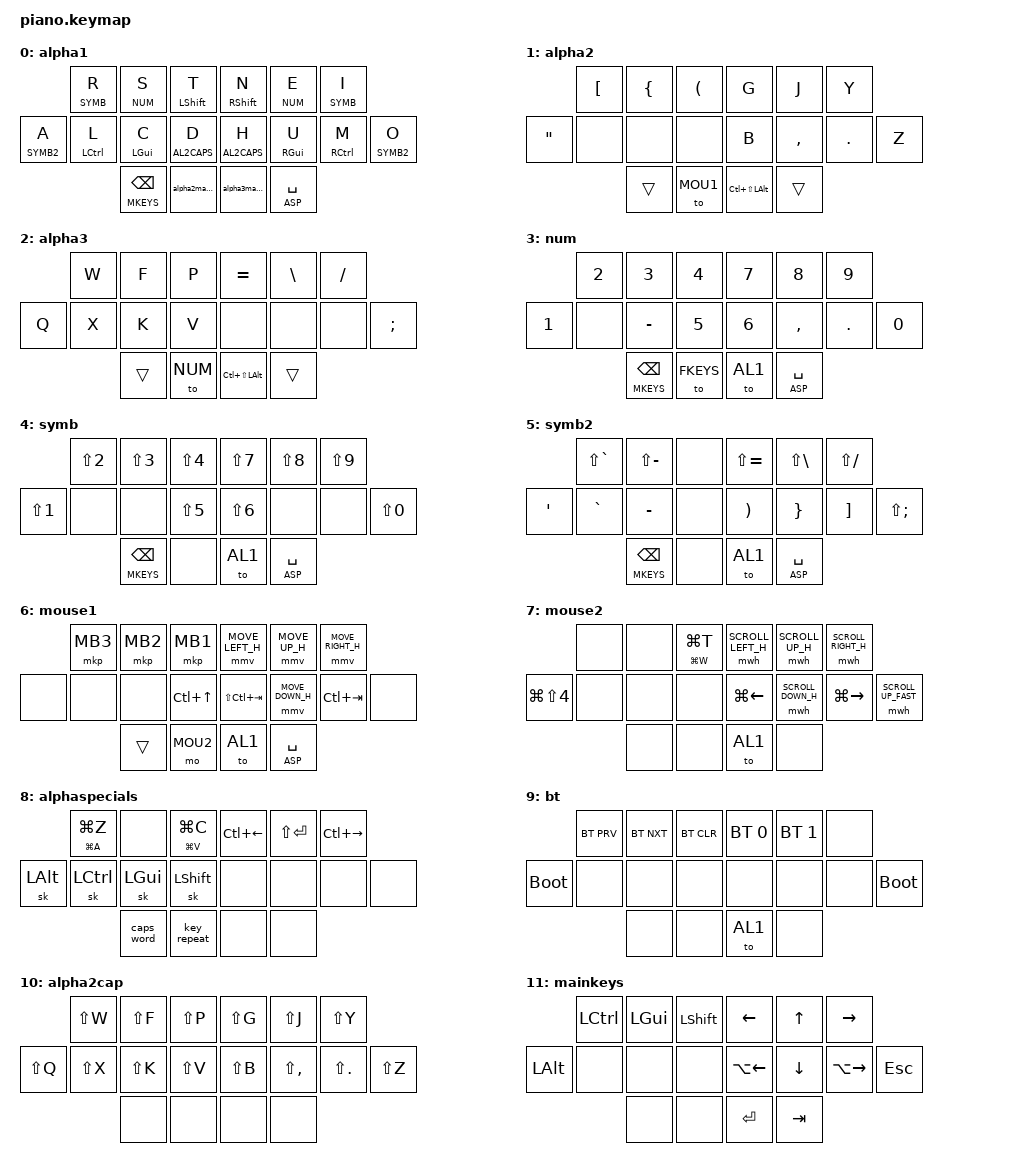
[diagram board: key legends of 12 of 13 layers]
/*
 * Copyright (c) 2020 The ZMK Contributors
 *
 * SPDX-License-Identifier: MIT
 */

#include <behaviors.dtsi>
#include <dt-bindings/zmk/keys.h>
#include <dt-bindings/zmk/bt.h>
#include <dt-bindings/zmk/mouse.h>

/* #define BL_ON_CMD 0 */
/* #define BL_OFF_CMD 1 */
/* #define BL_ON BL_ON_CMD 0 */
/* #define BL_OFF BL_OFF_CMD 0 */

#define M_MOVE_SPEED 1600
#define MOVE_UP_H MOVE_VERT(-M_MOVE_SPEED)
#define MOVE_DOWN_H MOVE_VERT(M_MOVE_SPEED)
#define MOVE_LEFT_H MOVE_HOR(-M_MOVE_SPEED)
#define MOVE_RIGHT_H MOVE_HOR(M_MOVE_SPEED)

#define M_SCROLL_SPEED 11
#define SCROLL_UP_H SCROLL_VERT(-M_SCROLL_SPEED)
#define SCROLL_DOWN_H SCROLL_VERT(M_SCROLL_SPEED)
#define SCROLL_LEFT_H SCROLL_HOR(-M_SCROLL_SPEED)
#define SCROLL_RIGHT_H SCROLL_HOR(M_SCROLL_SPEED)

#define SCROLL_UP_FAST SCROLL_VERT(-40)


&mt {
    tapping-term-ms = <201>;
    flavor = "tap-preferred";
 };
&sk {
     release-after-ms = <2000>;
     quick-release;
 };

&mmv {
  delay-ms = <0>;
  time-to-max-speed-ms = <500>;
  acceleration-exponent = <1>;
};

&mwh {
  delay-ms = <0>;
  time-to-max-speed-ms = <250>;
  acceleration-exponent = <0>;
};

/* Layers */
#define AL1       0
#define AL2       1
#define AL3       2
#define NUM       3
#define SYMB      4
#define SYMB2     5
#define MOU1      6
#define MOU2      7
#define ASP       8
#define BT        9
#define AL2CAPS   10
#define MKEYS     11
#define FKEYS     12

/ { 

    behaviors {
        thu_l: homerow_layers_left {
            compatible = "zmk,behavior-hold-tap";
            label = "THUMB_MODS_L";
            #binding-cells = <2>;
            tapping-term-ms = <120>;
            quick-tap-ms = <250>;
            flavor = "tap-preferred";
            bindings = <&mo>, <&kp>;
        };
        thu_r: homerow_layers_right {
            compatible = "zmk,behavior-hold-tap";
            label = "THUMB_MODS_R";
            #binding-cells = <2>;
            tapping-term-ms = <120>;
            quick-tap-ms = <250>;
            flavor = "tap-preferred";
            bindings = <&mo>, <&kp>;
        };
        hm_l: homerow_mods_left {
            compatible = "zmk,behavior-hold-tap";
            label = "HOMEROW_MODS_L";
            #binding-cells = <2>;
            tapping-term-ms = <250>;
            quick-tap-ms = <250>;
            flavor = "tap-preferred";
            bindings = <&kp>, <&kp>;
        };
        hm_r: homerow_mods_right {
            compatible = "zmk,behavior-hold-tap";
            label = "HOMEROW_MODS_R";
            #binding-cells = <2>;
            tapping-term-ms = <250>;
            quick-tap-ms = <250>;
            flavor = "tap-preferred";
            bindings = <&kp>, <&kp>;
        };
        hl_l: homerow_layers_left {
            compatible = "zmk,behavior-hold-tap";
            label = "HOMEROW_LAYERS_L";
            #binding-cells = <2>;
            tapping-term-ms = <250>;
            quick-tap-ms = <250>;
            flavor = "tap-preferred";
            bindings = <&mo>, <&kp>;
        };
        hl_r: homerow_layers_right {
            compatible = "zmk,behavior-hold-tap";
            label = "HOMEROW_LAYERS_R";
            #binding-cells = <2>;
            tapping-term-ms = <250>;
            quick-tap-ms = <250>;
            flavor = "tap-preferred";
            bindings = <&mo>, <&kp>;
        };
        td: tapdance {
            compatible = "zmk,behavior-hold-tap";
            label = "TAPDANCE";
            #binding-cells = <2>;
            tapping-term-ms = <190>;
            quick-tap-ms = <250>;
            flavor = "tap-preferred";
            bindings = <&kp>, <&kp>;
        };
	alpha2macro: behavior_macro_1 {
		compatible = "zmk,behavior-macro";
		label = "MACRO1";
		#binding-cells = <0>;
		bindings = < &sl AL2 >;
	};
	alpha3macro: behavior_macro_2 {
		compatible = "zmk,behavior-macro";
		label = "MACRO2";
		#binding-cells = <0>;
		bindings = < &sl AL3 >;
	};
	/* enter_bt_lay: behavior_macro_3 { */
	/* 	compatible = "zmk,behavior-macro"; */
	/* 	label = "BT backlight ON"; */
	/* 	#binding-cells = <0>; */
	/* 	bindings =    < &to BT > */
 /*                , < &bl BL_ON > */
 /*                ; */
	/* }; */
	/* leave_bt_lay: behavior_macro_4 { */
	/* 	compatible = "zmk,behavior-macro"; */
	/* 	label = "BT backlight OFF"; */
	/* 	#binding-cells = <0>; */
	/* 	bindings =    < &to AL1 > */
 /*                , < &bl BL_OFF > */
 /*                ; */
	/* }; */

    };
// 				0		1		2					3		  4			5
// 		6		7		8		9 				10		11		12 		13
//						14	15 	      16 	  17		
       keymap {
                compatible = "zmk,keymap";
                
    alpha1 {
		bindings = <
		 		            &hl_l SYMB R 	  &hl_l NUM S 	      &hm_l LSHIFT T		  &hm_r RSHIFT N 	  &hl_r NUM E     &hl_r SYMB I	  
		&hl_l SYMB2 A	  &hm_l LCTRL L	  &hm_l LGUI C	      &hl_l AL2CAPS D 	 	&hl_r AL2CAPS H   &hm_r RGUI U    &hm_r RCTRL M  &hl_r SYMB2 O
			 	 		 		                    &thu_l MKEYS BKSP   &alpha2macro        &alpha3macro	    &thu_r ASP SPC	 	
		>;
		};

    alpha2 {
		bindings = <
		 	 	                &kp LEFT_BRACKET 	&kp LEFT_BRACE	  &kp LEFT_PARENTHESIS	  &kp G    	        &kp J			    &kp Y 		
		&kp DOUBLE_QUOTES	 	&none		          &none		          &none                   &kp B 		        &kp COMMA			&kp DOT		&kp Z 
			 	 		 		                          &trans	          &to MOU1                &kp LC(LS(LALT))  &trans
		>;
		};

    alpha3 {
		bindings = <
		 	 	    &kp W 		&kp F		&kp P	 	 	&kp EQUAL    	      &kp BACKSLASH		&kp SLASH 		
		&kp Q	 	&kp X 		&kp K		&kp V 		&none 	            &none			      &none		&kp SEMICOLON 
			 	 		 		      &trans	&to NUM   &kp LC(LS(LALT))    &trans
		>;
		};
		
		num {
		bindings = <
		        &kp N2 	    &kp N3	            &kp N4 		  &kp N7 	  &kp N8		      &kp N9
		&kp N1	&none 	    &kp MINUS		        &kp N5		  &kp N6	  &kp COMMA	      &kp DOT   	&kp N0
		                    &hl_l MKEYS BKSP 		&to FKEYS   &to AL1 	&hl_r ASP SPC  	 
		>;
		};

		symb {
		bindings = <
		            &kp LS(N2) 	&kp LS(N3)	        &kp LS(N4) 		&kp LS(N7) 	  &kp LS(N8)		  &kp LS(N9)
		&kp LS(N1)	&none 	    &none		            &kp LS(N5)		&kp LS(N6)	  &none	          &none   	  &kp LS(N0)
		                        &hl_l MKEYS BKSP 		&none         &to AL1 	    &hl_r ASP SPC  	 
		>;
		};

		symb2 {
		bindings = <
		                    &kp LS(GRAVE) 	&kp LS(MINUS)	    &none 	&kp LS(EQUAL) 	        &kp LS(BACKSLASH)		&kp LS(SLASH)
		&kp SINGLE_QUOTE	  &kp GRAVE 	    &kp MINUS		      &none		&kp RIGHT_PARENTHESIS	  &kp RIGHT_BRACE	    &kp RIGHT_BRACKET   &kp LS(SEMICOLON)
		                                    &hl_l MKEYS BKSP  &none   &to AL1 	              &hl_r ASP SPC  	 
		>;
		};

		mouse1 {
		bindings = <
				 	&mkp  MB3		&mkp MB2 	&mkp MB1		&mmv MOVE_LEFT_H 	  &mmv MOVE_UP_H 		&mmv MOVE_RIGHT_H 			
		&none	&none		    &none 	  &kp LC(UP)	&kp LS(LC(TAB))  	  &mmv MOVE_DOWN_H 	&kp LC(TAB) 	     &none 
		 			 		 				&trans 		&mo MOU2    &to AL1             &hl_r ASP SPC		
		>;
		};

		mouse2 {
		bindings = <
				 	          &none	      &none	      &td LG(W) LG(T)	   &mwh SCROLL_LEFT_H   &mwh SCROLL_UP_H 		&mwh SCROLL_RIGHT_H
		&kp LG(LS(N4))	&none		    &none 	    &none		           &kp LG(LEFT)  		    &mwh SCROLL_DOWN_H  &kp LG(RIGHT) 	    &mwh SCROLL_UP_FAST
		 			 		 				          &none 		  &none              &to AL1              &none	
		>;
		};

		alphaspecials {
		bindings = <
				 	      &td LG(A) LG(Z) 	  &none	        &td LG(V) LG(C)	    &kp LC(LEFT) 	&kp LS(ENTER) 		&kp LC(RIGHT) 			
		&sk LALT    &sk LCTRL           &sk LGUI 	    &sk LSHIFT		        &none  		    &none 	          &none 	          &none 
		 			 		 			                &caps_word 		&key_repeat           &none         &none		
		>;
		};

		bt {
		bindings = <
				            &bt BT_PRV	&bt BT_NXT	&bt BT_CLR 			&bt BT_SEL 0 	  &bt BT_SEL 1	  &none	
		&bootloader  	  &none 		  &none 		  &none 			    &none 	        &none 	        &none	  &bootloader
		 	 	 				                &none	      &none           &to AL1	        &none
		>;
		};

    alpha2cap {
		bindings = <
		 	 	        &kp LS(W)	  &kp LS(F)	  &kp LS(P) 	&kp LS(G)   &kp LS(J)		  &kp LS(Y)	
		&kp LS(Q) 	&kp LS(X) 	&kp LS(K)	  &kp LS(V)		&kp LS(B)	  &kp LS(COMMA)	&kp LS(DOT)	&kp LS(Z) 
			 	                    &none 		  &none 			&none	      &none
		>;
		};
        
		mainkeys {
		bindings = <
				 	      &kp LCTRL		&kp LGUI 	&kp LSHIFT		&kp LEFT 	      &kp UP 		  &kp RIGHT 			
		&kp LALT	  &none		    &none 	  &none		      &kp LA(LEFT)    &kp DOWN  	&kp LA(RIGHT) 	&kp ESC 
		 			 		 				      &none 		&none         &kp ENTER       &kp TAB		
		>;
		};

		fkeys {
		bindings = <
				    &kp F1 	&kp F2	  &kp F3 		      &kp F7    &kp F8		&kp F9	
		&none	  &kp F4 	&kp F5		&kp F6		      &kp F10		&kp F11	  &kp F12   	&none
							      &none 		&to BT 	        &to AL1 	&none  	 
		>;
		};

	};
};
